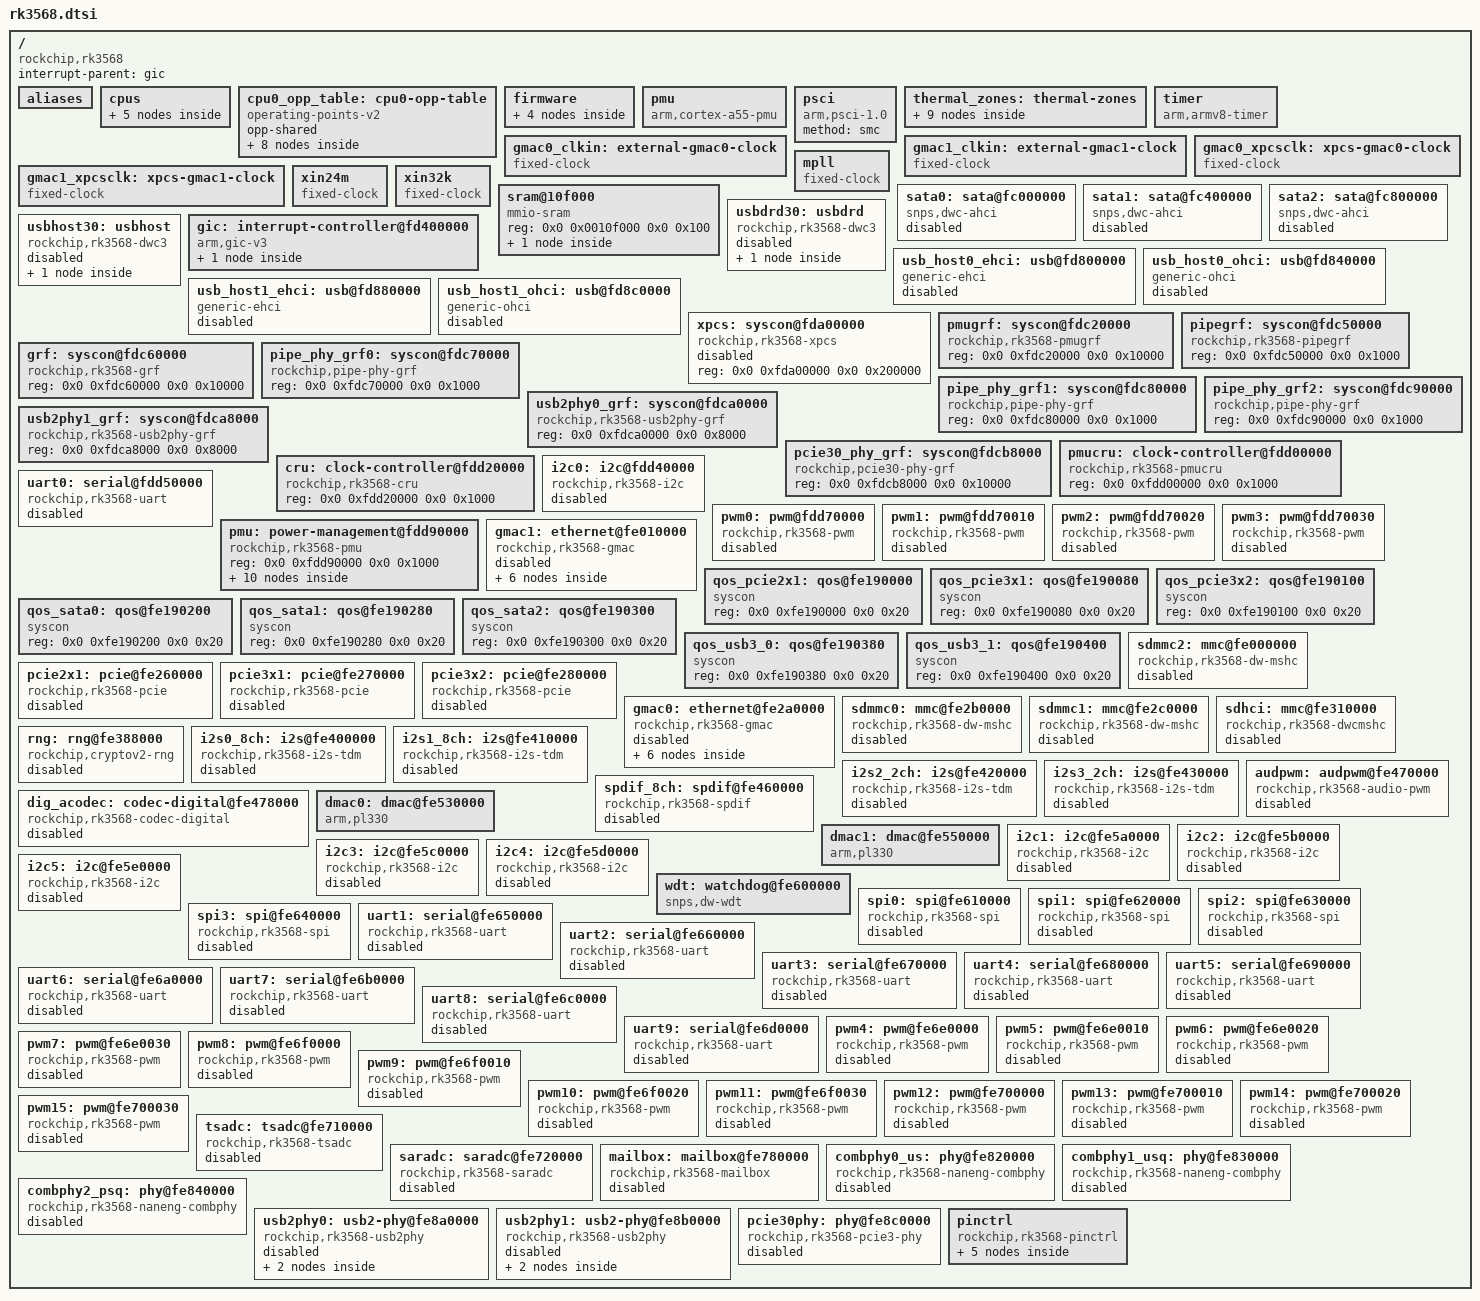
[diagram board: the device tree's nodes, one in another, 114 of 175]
// SPDX-License-Identifier: (GPL-2.0+ OR MIT)
/*
 * Copyright (c) 2021 Rockchip Electronics Co., Ltd.
 */

#include <dt-bindings/clock/rk3568-cru.h>
#include <dt-bindings/interrupt-controller/arm-gic.h>
#include <dt-bindings/interrupt-controller/irq.h>
#include <dt-bindings/phy/phy.h>
#include <dt-bindings/pinctrl/rockchip.h>
#include <dt-bindings/power/rk3568-power.h>
#include <dt-bindings/soc/rockchip,boot-mode.h>
#include <dt-bindings/thermal/thermal.h>

/ {
	compatible = "rockchip,rk3568";

	interrupt-parent = <&gic>;
	#address-cells = <2>;
	#size-cells = <2>;

	aliases {
		ethernet0 = &gmac0;
		ethernet1 = &gmac1;
		gpio0 = &gpio0;
		gpio1 = &gpio1;
		gpio2 = &gpio2;
		gpio3 = &gpio3;
		gpio4 = &gpio4;
		i2c0 = &i2c0;
		i2c1 = &i2c1;
		i2c2 = &i2c2;
		i2c3 = &i2c3;
		i2c4 = &i2c4;
		i2c5 = &i2c5;
		serial0 = &uart0;
		serial1 = &uart1;
		serial2 = &uart2;
		serial3 = &uart3;
		serial4 = &uart4;
		serial5 = &uart5;
		serial6 = &uart6;
		serial7 = &uart7;
		serial8 = &uart8;
		serial9 = &uart9;
		spi0 = &spi0;
		spi1 = &spi1;
		spi2 = &spi2;
		spi3 = &spi3;
	};

	cpus {
		#address-cells = <2>;
		#size-cells = <0>;

		cpu0: cpu@0 {
			device_type = "cpu";
			compatible = "arm,cortex-a55";
			reg = <0x0 0x0>;
			clocks = <&scmi_clk 0>;
			enable-method = "psci";
			operating-points-v2 = <&cpu0_opp_table>;
			#cooling-cells = <2>;
			dynamic-power-coefficient = <187>;
			power-model {
				compatible = "simple-power-model";
				leakage-range= <10 40>;
				ls = <(-9196) 6360 0>;
				static-coefficient = <100000>;
				ts = <83822 206397 (-4300) 71>;
				thermal-zone = "soc-thermal";
			};
		};

		cpu1: cpu@100 {
			device_type = "cpu";
			compatible = "arm,cortex-a55";
			reg = <0x0 0x100>;
			clocks = <&scmi_clk 0>;
			enable-method = "psci";
			operating-points-v2 = <&cpu0_opp_table>;
		};

		cpu2: cpu@200 {
			device_type = "cpu";
			compatible = "arm,cortex-a55";
			reg = <0x0 0x200>;
			clocks = <&scmi_clk 0>;
			enable-method = "psci";
			operating-points-v2 = <&cpu0_opp_table>;
		};

		cpu3: cpu@300 {
			device_type = "cpu";
			compatible = "arm,cortex-a55";
			reg = <0x0 0x300>;
			clocks = <&scmi_clk 0>;
			enable-method = "psci";
			operating-points-v2 = <&cpu0_opp_table>;
		};
	};

	cpu0_opp_table: cpu0-opp-table {
		compatible = "operating-points-v2";
		opp-shared;

		opp-408000000 {
			opp-hz = /bits/ 64 <408000000>;
			opp-microvolt = <900000 900000 1150000>;
			clock-latency-ns = <40000>;
		};

		opp-600000000 {
			opp-hz = /bits/ 64 <600000000>;
			opp-microvolt = <900000 900000 1150000>;
			clock-latency-ns = <40000>;
		};

		opp-816000000 {
			opp-hz = /bits/ 64 <816000000>;
			opp-microvolt = <900000 900000 1150000>;
			clock-latency-ns = <40000>;
			opp-suspend;
		};

		opp-1104000000 {
			opp-hz = /bits/ 64 <1104000000>;
			opp-microvolt = <900000 900000 1150000>;
			clock-latency-ns = <40000>;
		};

		opp-1416000000 {
			opp-hz = /bits/ 64 <1416000000>;
			opp-microvolt = <900000 900000 1150000>;
			clock-latency-ns = <40000>;
		};

		opp-1608000000 {
			opp-hz = /bits/ 64 <1608000000>;
			opp-microvolt = <975000 975000 1150000>;
			clock-latency-ns = <40000>;
		};

		opp-1800000000 {
			opp-hz = /bits/ 64 <1800000000>;
			opp-microvolt = <1050000 1050000 1150000>;
			clock-latency-ns = <40000>;
		};

		opp-1992000000 {
			opp-hz = /bits/ 64 <1992000000>;
			opp-microvolt = <1150000 1150000 1150000>;
			clock-latency-ns = <40000>;
		};
	};

	firmware {
		optee: optee {
			compatible = "linaro,optee-tz";
			method = "smc";
		};

		scmi: scmi {
			compatible = "arm,scmi-smc";
			arm,smc-id = <0x82000010>;
			shmem = <&scmi_shmem>;
			#address-cells = <1>;
			#size-cells = <0>;

			scmi_clk: protocol@14 {
				reg = <0x14>;
				#clock-cells = <1>;
			};
		};

		sdei: sdei {
			compatible = "arm,sdei-1.0";
			method = "smc";
		};
	};

	pmu {
		compatible = "arm,cortex-a55-pmu";
		interrupts = <GIC_SPI 228 IRQ_TYPE_LEVEL_HIGH>,
			     <GIC_SPI 229 IRQ_TYPE_LEVEL_HIGH>,
			     <GIC_SPI 230 IRQ_TYPE_LEVEL_HIGH>,
			     <GIC_SPI 231 IRQ_TYPE_LEVEL_HIGH>;
		interrupt-affinity = <&cpu0>, <&cpu1>, <&cpu2>, <&cpu3>;
	};

	psci {
		compatible = "arm,psci-1.0";
		method = "smc";
	};

	thermal_zones: thermal-zones {
		soc_thermal: soc-thermal {
			polling-delay-passive = <20>; /* milliseconds */
			polling-delay = <1000>; /* milliseconds */
			sustainable-power = <1475>; /* milliwatts */

			thermal-sensors = <&tsadc 0>;
			trips {
				threshold: trip-point-0 {
					temperature = <70000>;
					hysteresis = <2000>;
					type = "passive";
				};
				target: trip-point-1 {
					temperature = <85000>;
					hysteresis = <2000>;
					type = "passive";
				};
				soc_crit: soc-crit {
					/* millicelsius */
					temperature = <115000>;
					/* millicelsius */
					hysteresis = <2000>;
					type = "critical";
				};
			};
			cooling-maps {
				map0 {
					trip = <&target>;
					cooling-device = <&cpu0 THERMAL_NO_LIMIT THERMAL_NO_LIMIT>;
					contribution = <1024>;
				};
				map1 {
					trip = <&target>;
					cooling-device = <&gpu THERMAL_NO_LIMIT THERMAL_NO_LIMIT>;
					contribution = <1024>;
				};
			};
		};

		gpu_thermal: gpu-thermal {
			polling-delay-passive = <20>; /* milliseconds */
			polling-delay = <1000>; /* milliseconds */

			thermal-sensors = <&tsadc 1>;
		};
	};

	timer {
		compatible = "arm,armv8-timer";
		interrupts = <GIC_PPI 13 IRQ_TYPE_LEVEL_HIGH>,
			     <GIC_PPI 14 IRQ_TYPE_LEVEL_HIGH>,
			     <GIC_PPI 11 IRQ_TYPE_LEVEL_HIGH>,
			     <GIC_PPI 10 IRQ_TYPE_LEVEL_HIGH>;
		arm,no-tick-in-suspend;
	};

	gmac0_clkin: external-gmac0-clock {
		compatible = "fixed-clock";
		clock-frequency = <125000000>;
		clock-output-names = "gmac0_clkin";
		#clock-cells = <0>;
	};

	gmac1_clkin: external-gmac1-clock {
		compatible = "fixed-clock";
		clock-frequency = <125000000>;
		clock-output-names = "gmac1_clkin";
		#clock-cells = <0>;
	};

	gmac0_xpcsclk: xpcs-gmac0-clock {
		compatible = "fixed-clock";
		clock-frequency = <125000000>;
		clock-output-names = "clk_gmac0_xpcs_mii";
		#clock-cells = <0>;
	};

	gmac1_xpcsclk: xpcs-gmac1-clock {
		compatible = "fixed-clock";
		clock-frequency = <125000000>;
		clock-output-names = "clk_gmac1_xpcs_mii";
		#clock-cells = <0>;
	};

	mpll: mpll {
		compatible = "fixed-clock";
		clock-frequency = <800000000>;
		clock-output-names = "mpll";
		#clock-cells = <0>;
	};

	xin24m: xin24m {
		compatible = "fixed-clock";
		clock-frequency = <24000000>;
		clock-output-names = "xin24m";
		#clock-cells = <0>;
	};

	xin32k: xin32k {
		compatible = "fixed-clock";
		clock-frequency = <32768>;
		clock-output-names = "xin32k";
		pinctrl-0 = <&clk32k_out0>;
		pinctrl-names = "default";
		#clock-cells = <0>;
	};

	sram@10f000 {
		compatible = "mmio-sram";
		reg = <0x0 0x0010f000 0x0 0x100>;
		#address-cells = <1>;
		#size-cells = <1>;
		ranges = <0 0x0 0x0010f000 0x100>;

		scmi_shmem: sram@0 {
			compatible = "arm,scmi-shmem";
			reg = <0x0 0x100>;
		};
	};

	sata0: sata@fc000000 {
		compatible = "snps,dwc-ahci";
		reg = <0 0xfc000000 0 0x1000>;
		clocks = <&cru ACLK_SATA0>, <&cru CLK_SATA0_PMALIVE>,
			 <&cru CLK_SATA0_RXOOB>;
		clock-names = "sata", "pmalive", "rxoob";
		interrupts = <GIC_SPI 94 IRQ_TYPE_LEVEL_HIGH>;
		interrupt-names = "hostc";
		phys = <&combphy0_us PHY_TYPE_SATA>;
		phy-names = "sata-phy";
		ports-implemented = <0x1>;
		power-domains = <&power RK3568_PD_PIPE>;
		status = "disabled";
	};

	sata1: sata@fc400000 {
		compatible = "snps,dwc-ahci";
		reg = <0 0xfc400000 0 0x1000>;
		clocks = <&cru ACLK_SATA1>, <&cru CLK_SATA1_PMALIVE>,
			 <&cru CLK_SATA1_RXOOB>;
		clock-names = "sata", "pmalive", "rxoob";
		interrupts = <GIC_SPI 95 IRQ_TYPE_LEVEL_HIGH>;
		interrupt-names = "hostc";
		phys = <&combphy1_usq PHY_TYPE_SATA>;
		phy-names = "sata-phy";
		ports-implemented = <0x1>;
		power-domains = <&power RK3568_PD_PIPE>;
		status = "disabled";
	};

	sata2: sata@fc800000 {
		compatible = "snps,dwc-ahci";
		reg = <0 0xfc800000 0 0x1000>;
		clocks = <&cru ACLK_SATA2>, <&cru CLK_SATA2_PMALIVE>,
			 <&cru CLK_SATA2_RXOOB>;
		clock-names = "sata", "pmalive", "rxoob";
		interrupts = <GIC_SPI 96 IRQ_TYPE_LEVEL_HIGH>;
		interrupt-names = "hostc";
		phys = <&combphy2_psq PHY_TYPE_SATA>;
		phy-names = "sata-phy";
		ports-implemented = <0x1>;
		power-domains = <&power RK3568_PD_PIPE>;
		status = "disabled";
	};

	usbdrd30: usbdrd {
		compatible = "rockchip,rk3568-dwc3", "rockchip,rk3399-dwc3";
		clocks = <&cru CLK_USB3OTG0_REF>, <&cru CLK_USB3OTG0_SUSPEND>,
			 <&cru ACLK_USB3OTG0>, <&cru PCLK_PIPE>;
		clock-names = "ref_clk", "suspend_clk",
			      "bus_clk", "pipe_clk";
		#address-cells = <2>;
		#size-cells = <2>;
		ranges;
		status = "disabled";

		usbdrd_dwc3: dwc3@fcc00000 {
			compatible = "snps,dwc3";
			reg = <0x0 0xfcc00000 0x0 0x400000>;
			interrupts = <GIC_SPI 169 IRQ_TYPE_LEVEL_HIGH>;
			dr_mode = "otg";
			phys = <&u2phy0_otg>, <&combphy0_us PHY_TYPE_USB3>;
			phy-names = "usb2-phy", "usb3-phy";
			phy_type = "utmi_wide";
			power-domains = <&power RK3568_PD_PIPE>;
			resets = <&cru SRST_USB3OTG0>;
			reset-names = "usb3-otg";
			snps,dis_enblslpm_quirk;
			snps,dis-u2-freeclk-exists-quirk;
			snps,dis-del-phy-power-chg-quirk;
			snps,dis-tx-ipgap-linecheck-quirk;
			snps,xhci-trb-ent-quirk;
			status = "disabled";
		};
	};

	usbhost30: usbhost {
		compatible = "rockchip,rk3568-dwc3", "rockchip,rk3399-dwc3";
		clocks = <&cru CLK_USB3OTG1_REF>, <&cru CLK_USB3OTG1_SUSPEND>,
			 <&cru ACLK_USB3OTG1>, <&cru PCLK_PIPE>;
		clock-names = "ref_clk", "suspend_clk",
			      "bus_clk", "pipe_clk";
		#address-cells = <2>;
		#size-cells = <2>;
		ranges;
		status = "disabled";

		usbhost_dwc3: dwc3@fd000000 {
			compatible = "snps,dwc3";
			reg = <0x0 0xfd000000 0x0 0x400000>;
			interrupts = <GIC_SPI 170 IRQ_TYPE_LEVEL_HIGH>;
			dr_mode = "host";
			phys = <&u2phy0_host>, <&combphy1_usq PHY_TYPE_USB3>;
			phy-names = "usb2-phy", "usb3-phy";
			phy_type = "utmi_wide";
			power-domains = <&power RK3568_PD_PIPE>;
			resets = <&cru SRST_USB3OTG1>;
			reset-names = "usb3-host";
			snps,dis_enblslpm_quirk;
			snps,dis-u2-freeclk-exists-quirk;
			snps,dis-del-phy-power-chg-quirk;
			snps,dis-tx-ipgap-linecheck-quirk;
			snps,xhci-trb-ent-quirk;
			status = "disabled";
		};
	};

	gic: interrupt-controller@fd400000 {
		compatible = "arm,gic-v3";
		#interrupt-cells = <3>;
		#address-cells = <2>;
		#size-cells = <2>;
		ranges;
		interrupt-controller;

		reg = <0x0 0xfd400000 0 0x10000>, /* GICD */
		      <0x0 0xfd460000 0 0xc0000>; /* GICR */
		interrupts = <GIC_PPI 9 IRQ_TYPE_LEVEL_HIGH>;
		its: interrupt-controller@fd440000 {
			compatible = "arm,gic-v3-its";
			msi-controller;
			#msi-cells = <1>;
			reg = <0x0 0xfd440000 0x0 0x20000>;
		};
	};

	usb_host0_ehci: usb@fd800000 {
		compatible = "generic-ehci";
		reg = <0x0 0xfd800000 0x0 0x40000>;
		interrupts = <GIC_SPI 130 IRQ_TYPE_LEVEL_HIGH>;
		clocks = <&cru HCLK_USB2HOST0>, <&cru HCLK_USB2HOST0_ARB>,
			 <&cru PCLK_USB>, <&usb2phy1>;
		clock-names = "usbhost", "arbiter", "pclk", "utmi";
		phys = <&u2phy1_otg>;
		phy-names = "usb2-phy";
		status = "disabled";
	};

	usb_host0_ohci: usb@fd840000 {
		compatible = "generic-ohci";
		reg = <0x0 0xfd840000 0x0 0x40000>;
		interrupts = <GIC_SPI 131 IRQ_TYPE_LEVEL_HIGH>;
		clocks = <&cru HCLK_USB2HOST0>, <&cru HCLK_USB2HOST0_ARB>,
			 <&cru PCLK_USB>, <&usb2phy1>;
		clock-names = "usbhost", "arbiter", "pclk", "utmi";
		phys = <&u2phy1_otg>;
		phy-names = "usb2-phy";
		status = "disabled";
	};

	usb_host1_ehci: usb@fd880000 {
		compatible = "generic-ehci";
		reg = <0x0 0xfd880000 0x0 0x40000>;
		interrupts = <GIC_SPI 133 IRQ_TYPE_LEVEL_HIGH>;
		clocks = <&cru HCLK_USB2HOST1>, <&cru HCLK_USB2HOST1_ARB>,
			 <&cru PCLK_USB>, <&usb2phy1>;
		clock-names = "usbhost", "arbiter", "pclk", "utmi";
		phys = <&u2phy1_host>;
		phy-names = "usb2-phy";
		status = "disabled";
	};

	usb_host1_ohci: usb@fd8c0000 {
		compatible = "generic-ohci";
		reg = <0x0 0xfd8c0000 0x0 0x40000>;
		interrupts = <GIC_SPI 134 IRQ_TYPE_LEVEL_HIGH>;
		clocks = <&cru HCLK_USB2HOST1>, <&cru HCLK_USB2HOST1_ARB>,
			 <&cru PCLK_USB>, <&usb2phy1>;
		clock-names = "usbhost", "arbiter", "pclk", "utmi";
		phys = <&u2phy1_host>;
		phy-names = "usb2-phy";
		status = "disabled";
	};

	xpcs: syscon@fda00000 {
		compatible = "rockchip,rk3568-xpcs", "syscon";
		reg = <0x0 0xfda00000 0x0 0x200000>;
		status = "disabled";
	};

	pmugrf: syscon@fdc20000 {
		compatible = "rockchip,rk3568-pmugrf", "syscon", "simple-mfd";
		reg = <0x0 0xfdc20000 0x0 0x10000>;
	};

	pipegrf: syscon@fdc50000 {
		compatible = "rockchip,rk3568-pipegrf", "syscon";
		reg = <0x0 0xfdc50000 0x0 0x1000>;
	};

	grf: syscon@fdc60000 {
		compatible = "rockchip,rk3568-grf", "syscon", "simple-mfd";
		reg = <0x0 0xfdc60000 0x0 0x10000>;
	};

	pipe_phy_grf0: syscon@fdc70000 {
		compatible = "rockchip,pipe-phy-grf", "syscon";
		reg = <0x0 0xfdc70000 0x0 0x1000>;
	};

	pipe_phy_grf1: syscon@fdc80000 {
		compatible = "rockchip,pipe-phy-grf", "syscon";
		reg = <0x0 0xfdc80000 0x0 0x1000>;
	};

	pipe_phy_grf2: syscon@fdc90000 {
		compatible = "rockchip,pipe-phy-grf", "syscon";
		reg = <0x0 0xfdc90000 0x0 0x1000>;
	};

	usb2phy0_grf: syscon@fdca0000 {
		compatible = "rockchip,rk3568-usb2phy-grf", "syscon";
		reg = <0x0 0xfdca0000 0x0 0x8000>;
	};

	usb2phy1_grf: syscon@fdca8000 {
		compatible = "rockchip,rk3568-usb2phy-grf", "syscon";
		reg = <0x0 0xfdca8000 0x0 0x8000>;
	};

	pcie30_phy_grf: syscon@fdcb8000 {
		compatible = "rockchip,pcie30-phy-grf", "syscon";
		reg = <0x0 0xfdcb8000 0x0 0x10000>;
	};

	pmucru: clock-controller@fdd00000 {
		compatible = "rockchip,rk3568-pmucru";
		reg = <0x0 0xfdd00000 0x0 0x1000>;
		#clock-cells = <1>;
		#reset-cells = <1>;
	};

	cru: clock-controller@fdd20000 {
		compatible = "rockchip,rk3568-cru";
		reg = <0x0 0xfdd20000 0x0 0x1000>;
		#clock-cells = <1>;
		#reset-cells = <1>;
	};

	i2c0: i2c@fdd40000 {
		compatible = "rockchip,rk3568-i2c", "rockchip,rk3399-i2c";
		reg = <0x0 0xfdd40000 0x0 0x1000>;
		interrupts = <GIC_SPI 46 IRQ_TYPE_LEVEL_HIGH>;
		clocks = <&pmucru CLK_I2C0>, <&pmucru PCLK_I2C0>;
		clock-names = "i2c", "pclk";
		pinctrl-0 = <&i2c0_xfer>;
		pinctrl-names = "default";
		#address-cells = <1>;
		#size-cells = <0>;
		status = "disabled";
	};

	uart0: serial@fdd50000 {
		compatible = "rockchip,rk3568-uart", "snps,dw-apb-uart";
		reg = <0x0 0xfdd50000 0x0 0x100>;
		interrupts = <GIC_SPI 116 IRQ_TYPE_LEVEL_HIGH>;
		clocks = <&pmucru SCLK_UART0>, <&pmucru PCLK_UART0>;
		clock-names = "baudclk", "apb_pclk";
		dmas = <&dmac0 0>, <&dmac0 1>;
		pinctrl-0 = <&uart0_xfer>;
		pinctrl-names = "default";
		reg-io-width = <4>;
		reg-shift = <2>;
		status = "disabled";
	};

	pwm0: pwm@fdd70000 {
		compatible = "rockchip,rk3568-pwm", "rockchip,rk3328-pwm";
		reg = <0x0 0xfdd70000 0x0 0x10>;
		#pwm-cells = <3>;
		pinctrl-names = "active";
		pinctrl-0 = <&pwm0m0_pins>;
		clocks = <&pmucru CLK_PWM0>, <&pmucru PCLK_PWM0>;
		clock-names = "pwm", "pclk";
		status = "disabled";
	};

	pwm1: pwm@fdd70010 {
		compatible = "rockchip,rk3568-pwm", "rockchip,rk3328-pwm";
		reg = <0x0 0xfdd70010 0x0 0x10>;
		#pwm-cells = <3>;
		pinctrl-names = "active";
		pinctrl-0 = <&pwm1m0_pins>;
		clocks = <&pmucru CLK_PWM0>, <&pmucru PCLK_PWM0>;
		clock-names = "pwm", "pclk";
		status = "disabled";
	};

	pwm2: pwm@fdd70020 {
		compatible = "rockchip,rk3568-pwm", "rockchip,rk3328-pwm";
		reg = <0x0 0xfdd70020 0x0 0x10>;
		#pwm-cells = <3>;
		pinctrl-names = "active";
		pinctrl-0 = <&pwm2m0_pins>;
		clocks = <&pmucru CLK_PWM0>, <&pmucru PCLK_PWM0>;
		clock-names = "pwm", "pclk";
		status = "disabled";
	};

	pwm3: pwm@fdd70030 {
		compatible = "rockchip,rk3568-pwm", "rockchip,rk3328-pwm";
		reg = <0x0 0xfdd70030 0x0 0x10>;
		#pwm-cells = <3>;
		pinctrl-names = "active";
		pinctrl-0 = <&pwm3_pins>;
		clocks = <&pmucru CLK_PWM0>, <&pmucru PCLK_PWM0>;
		clock-names = "pwm", "pclk";
		status = "disabled";
	};

	pmu: power-management@fdd90000 {
		compatible = "rockchip,rk3568-pmu", "syscon", "simple-mfd";
		reg = <0x0 0xfdd90000 0x0 0x1000>;

		power: power-controller {
			compatible = "rockchip,rk3568-power-controller";
			#power-domain-cells = <1>;
			#address-cells = <1>;
			#size-cells = <0>;
			status = "okay";

			/* These power domains are grouped by VD_NPU */
			pd_npu@RK3568_PD_NPU {
				reg = <RK3568_PD_NPU>;
				clocks = <&cru ACLK_NPU_PRE>,
					 <&cru HCLK_NPU_PRE>,
					 <&cru PCLK_NPU_PRE>;
				pm_qos = <&qos_npu>;
			};
			/* These power domains are grouped by VD_GPU */
			pd_gpu@RK3568_PD_GPU {
				reg = <RK3568_PD_GPU>;
				clocks = <&cru ACLK_GPU_PRE>,
					 <&cru PCLK_GPU_PRE>;
				pm_qos = <&qos_gpu>;
			};
			/* These power domains are grouped by VD_LOGIC */
			pd_vi@RK3568_PD_VI {
				reg = <RK3568_PD_VI>;
				clocks = <&cru HCLK_VI>,
					 <&cru PCLK_VI>;
				pm_qos = <&qos_isp>,
					 <&qos_vicap0>,
					 <&qos_vicap1>;
			};
			pd_vo@RK3568_PD_VO {
				reg = <RK3568_PD_VO>;
				clocks = <&cru HCLK_VO>,
					 <&cru PCLK_VO>,
					 <&cru ACLK_VOP_PRE>;
				pm_qos = <&qos_hdcp>,
					 <&qos_vop_m0>,
					 <&qos_vop_m1>;
			};
			pd_rga@RK3568_PD_RGA {
				reg = <RK3568_PD_RGA>;
				clocks = <&cru HCLK_RGA_PRE>,
					 <&cru PCLK_RGA_PRE>;
				pm_qos = <&qos_ebc>,
					 <&qos_iep>,
					 <&qos_jpeg_dec>,
					 <&qos_jpeg_enc>,
					 <&qos_rga_rd>,
					 <&qos_rga_wr>;
			};
			pd_vpu@RK3568_PD_VPU {
				reg = <RK3568_PD_VPU>;
				clocks = <&cru HCLK_VPU_PRE>;
				pm_qos = <&qos_vpu>;
			};
			pd_rkvdec@RK3568_PD_RKVDEC {
				clocks = <&cru HCLK_RKVDEC_PRE>;
				reg = <RK3568_PD_RKVDEC>;
				pm_qos = <&qos_rkvdec>;
			};
			pd_rkvenc@RK3568_PD_RKVENC {
				reg = <RK3568_PD_RKVENC>;
				clocks = <&cru HCLK_RKVENC_PRE>;
				pm_qos = <&qos_rkvenc_rd_m0>,
					 <&qos_rkvenc_rd_m1>,
					 <&qos_rkvenc_wr_m0>;
			};
			pd_pipe@RK3568_PD_PIPE {
				reg = <RK3568_PD_PIPE>;
				clocks = <&cru PCLK_PIPE>;
				pm_qos = <&qos_pcie2x1>,
					 <&qos_pcie3x1>,
					 <&qos_pcie3x2>,
					 <&qos_sata0>,
					 <&qos_sata1>,
					 <&qos_sata2>,
					 <&qos_usb3_0>,
					 <&qos_usb3_1>;
			};
		};
	};

	gmac1: ethernet@fe010000 {
		compatible = "rockchip,rk3568-gmac", "snps,dwmac-4.20a";
		reg = <0x0 0xfe010000 0x0 0x10000>;
		interrupts = <GIC_SPI 32 IRQ_TYPE_LEVEL_HIGH>,
			     <GIC_SPI 29 IRQ_TYPE_LEVEL_HIGH>;
		interrupt-names = "macirq", "eth_wake_irq";
		rockchip,grf = <&grf>;
		clocks = <&cru SCLK_GMAC1>, <&cru SCLK_GMAC1_RX_TX>,
			 <&cru SCLK_GMAC1_RX_TX>, <&cru CLK_MAC1_REFOUT>,
			 <&cru ACLK_GMAC1>, <&cru PCLK_GMAC1>,
			 <&cru SCLK_GMAC1_RX_TX>, <&cru CLK_GMAC1_PTP_REF>,
			 <&cru PCLK_XPCS>;
		clock-names = "stmmaceth", "mac_clk_rx",
			      "mac_clk_tx", "clk_mac_refout",
			      "aclk_mac", "pclk_mac",
			      "clk_mac_speed", "ptp_ref",
			      "pclk_xpcs";
		resets = <&cru SRST_A_GMAC1>;
		reset-names = "stmmaceth";

		snps,mixed-burst;
		snps,tso;

		snps,axi-config = <&gmac1_stmmac_axi_setup>;
		snps,mtl-rx-config = <&gmac1_mtl_rx_setup>;
		snps,mtl-tx-config = <&gmac1_mtl_tx_setup>;
		status = "disabled";

		mdio1: mdio {
			compatible = "snps,dwmac-mdio";
			#address-cells = <0x1>;
			#size-cells = <0x0>;
		};

		gmac1_stmmac_axi_setup: stmmac-axi-config {
			snps,wr_osr_lmt = <4>;
			snps,rd_osr_lmt = <8>;
			snps,blen = <0 0 0 0 16 8 4>;
		};

		gmac1_mtl_rx_setup: rx-queues-config {
			snps,rx-queues-to-use = <1>;
			queue0 {};
		};

		gmac1_mtl_tx_setup: tx-queues-config {
			snps,tx-queues-to-use = <1>;
			queue0 {};
		};
	};

	qos_pcie2x1: qos@fe190000 {
		compatible = "syscon";
		reg = <0x0 0xfe190000 0x0 0x20>;
	};

	qos_pcie3x1: qos@fe190080 {
		compatible = "syscon";
		reg = <0x0 0xfe190080 0x0 0x20>;
	};

	qos_pcie3x2: qos@fe190100 {
		compatible = "syscon";
		reg = <0x0 0xfe190100 0x0 0x20>;
	};

	qos_sata0: qos@fe190200 {
		compatible = "syscon";
		reg = <0x0 0xfe190200 0x0 0x20>;
	};

	qos_sata1: qos@fe190280 {
		compatible = "syscon";
		reg = <0x0 0xfe190280 0x0 0x20>;
	};

	qos_sata2: qos@fe190300 {
		compatible = "syscon";
		reg = <0x0 0xfe190300 0x0 0x20>;
	};

	qos_usb3_0: qos@fe190380 {
		compatible = "syscon";
		reg = <0x0 0xfe190380 0x0 0x20>;
	};

	qos_usb3_1: qos@fe190400 {
		compatible = "syscon";
		reg = <0x0 0xfe190400 0x0 0x20>;
	};

	sdmmc2: mmc@fe000000 {
		compatible = "rockchip,rk3568-dw-mshc", "rockchip,rk3288-dw-mshc";
		reg = <0x0 0xfe000000 0x0 0x4000>;
		interrupts = <GIC_SPI 100 IRQ_TYPE_LEVEL_HIGH>;
		clocks = <&cru HCLK_SDMMC2>, <&cru CLK_SDMMC2>,
			 <&cru SCLK_SDMMC2_DRV>, <&cru SCLK_SDMMC2_SAMPLE>;
		clock-names = "biu", "ciu", "ciu-drive", "ciu-sample";
		fifo-depth = <0x100>;
		max-frequency = <150000000>;
		resets = <&cru SRST_SDMMC2>;
		reset-names = "reset";
		status = "disabled";
	};

	pcie2x1: pcie@fe260000 {
		compatible = "rockchip,rk3568-pcie", "snps,dw-pcie";
		#address-cells = <3>;
		#size-cells = <2>;
		bus-range = <0x0 0xf>;
		clocks = <&cru ACLK_PCIE20_MST>, <&cru ACLK_PCIE20_SLV>,
			 <&cru ACLK_PCIE20_DBI>, <&cru PCLK_PCIE20>,
			 <&cru CLK_PCIE20_AUX_NDFT>;
		clock-names = "aclk_mst", "aclk_slv",
			      "aclk_dbi", "pclk", "aux";
		device_type = "pci";
		interrupts = <GIC_SPI 75 IRQ_TYPE_LEVEL_HIGH>,
			     <GIC_SPI 74 IRQ_TYPE_LEVEL_HIGH>,
			     <GIC_SPI 73 IRQ_TYPE_LEVEL_HIGH>,
			     <GIC_SPI 72 IRQ_TYPE_LEVEL_HIGH>,
			     <GIC_SPI 71 IRQ_TYPE_LEVEL_HIGH>;
		interrupt-names = "sys", "pmc", "msg", "legacy", "err";
		linux,pci-domain = <0>;
		num-ib-windows = <6>;
		num-ob-windows = <2>;
		max-link-speed = <2>;
		msi-map = <0x0 &its 0x0 0x1000>;
		num-lanes = <1>;
		phys = <&combphy2_psq PHY_TYPE_PCIE>;
		phy-names = "pcie-phy";
		power-domains = <&power RK3568_PD_PIPE>;
		ranges = <0x00000800 0x0 0x00000000 0x3 0x00000000 0x0 0x800000
			  0x81000000 0x0 0x00800000 0x3 0x00800000 0x0 0x100000
			  0x83000000 0x0 0x00900000 0x3 0x00900000 0x0 0x3f700000>;
		reg = <0x3 0xc0000000 0x0 0x400000>,
		      <0x0 0xfe260000 0x0 0x10000>;
		reg-names = "pcie-dbi", "pcie-apb";
		resets = <&cru SRST_PCIE20_POWERUP>;
		reset-names = "pipe";
		status = "disabled";
	};

	pcie3x1: pcie@fe270000 {
		compatible = "rockchip,rk3568-pcie", "snps,dw-pcie";
		#address-cells = <3>;
		#size-cells = <2>;
		bus-range = <0x10 0x1f>;
		clocks = <&cru ACLK_PCIE30X1_MST>, <&cru ACLK_PCIE30X1_SLV>,
			 <&cru ACLK_PCIE30X1_DBI>, <&cru PCLK_PCIE30X1>,
			 <&cru CLK_PCIE30X1_AUX_NDFT>;
		clock-names = "aclk_mst", "aclk_slv",
			      "aclk_dbi", "pclk", "aux";
		device_type = "pci";
		interrupts = <GIC_SPI 160 IRQ_TYPE_LEVEL_HIGH>,
			     <GIC_SPI 159 IRQ_TYPE_LEVEL_HIGH>,
			     <GIC_SPI 158 IRQ_TYPE_LEVEL_HIGH>,
			     <GIC_SPI 157 IRQ_TYPE_LEVEL_HIGH>,
			     <GIC_SPI 156 IRQ_TYPE_LEVEL_HIGH>;
		interrupt-names = "sys", "pmc", "msg", "legacy", "err";
		linux,pci-domain = <1>;
		num-ib-windows = <6>;
		num-ob-windows = <2>;
		max-link-speed = <3>;
		msi-map = <0x1000 &its 0x1000 0x1000>;
		num-lanes = <1>;
		phys = <&pcie30phy>;
		phy-names = "pcie-phy";
		power-domains = <&power RK3568_PD_PIPE>;
		ranges = <0x00000800 0x0 0x40000000 0x3 0x40000000 0x0 0x800000
			  0x81000000 0x0 0x40800000 0x3 0x40800000 0x0 0x100000
			  0x83000000 0x0 0x40900000 0x3 0x40900000 0x0 0x3f700000>;
		reg = <0x3 0xc0400000 0x0 0x400000>,
		      <0x0 0xfe270000 0x0 0x10000>;
		reg-names = "pcie-dbi", "pcie-apb";
		resets = <&cru SRST_PCIE30X1_POWERUP>;
		reset-names = "pipe";
		/* rockchip,bifurcation; lane1 when using 1+1 */
		status = "disabled";
	};

	pcie3x2: pcie@fe280000 {
		compatible = "rockchip,rk3568-pcie", "snps,dw-pcie";
		#address-cells = <3>;
		#size-cells = <2>;
		bus-range = <0x20 0x2f>;
		clocks = <&cru ACLK_PCIE30X2_MST>, <&cru ACLK_PCIE30X2_SLV>,
			 <&cru ACLK_PCIE30X2_DBI>, <&cru PCLK_PCIE30X2>,
			 <&cru CLK_PCIE30X2_AUX_NDFT>;
		clock-names = "aclk_mst", "aclk_slv",
			      "aclk_dbi", "pclk", "aux";
		device_type = "pci";
		interrupts = <GIC_SPI 165 IRQ_TYPE_LEVEL_HIGH>,
			     <GIC_SPI 164 IRQ_TYPE_LEVEL_HIGH>,
			     <GIC_SPI 163 IRQ_TYPE_LEVEL_HIGH>,
			     <GIC_SPI 162 IRQ_TYPE_LEVEL_HIGH>,
			     <GIC_SPI 161 IRQ_TYPE_LEVEL_HIGH>;
		interrupt-names = "sys", "pmc", "msg", "legacy", "err";
		linux,pci-domain = <2>;
		num-ib-windows = <6>;
		num-ob-windows = <2>;
		max-link-speed = <3>;
		msi-map = <0x2000 &its 0x2000 0x1000>;
		num-lanes = <2>;
		phys = <&pcie30phy>;
		phy-names = "pcie-phy";
		power-domains = <&power RK3568_PD_PIPE>;
		ranges = <0x00000800 0x0 0x80000000 0x3 0x80000000 0x0 0x800000
			  0x81000000 0x0 0x80800000 0x3 0x80800000 0x0 0x100000
			  0x83000000 0x0 0x80900000 0x3 0x80900000 0x0 0x3f700000>;
		reg = <0x3 0xc0800000 0x0 0x400000>,
		      <0x0 0xfe280000 0x0 0x10000>;
		reg-names = "pcie-dbi", "pcie-apb";
		resets = <&cru SRST_PCIE30X2_POWERUP>;
		reset-names = "pipe";
		/* rockchip,bifurcation; lane0 when using 1+1 */
		status = "disabled";
	};

	gmac0: ethernet@fe2a0000 {
		compatible = "rockchip,rk3568-gmac", "snps,dwmac-4.20a";
		reg = <0x0 0xfe2a0000 0x0 0x10000>;
		interrupts = <GIC_SPI 27 IRQ_TYPE_LEVEL_HIGH>,
			     <GIC_SPI 24 IRQ_TYPE_LEVEL_HIGH>;
		interrupt-names = "macirq", "eth_wake_irq";
		rockchip,grf = <&grf>;
		clocks = <&cru SCLK_GMAC0>, <&cru SCLK_GMAC0_RX_TX>,
			 <&cru SCLK_GMAC0_RX_TX>, <&cru CLK_MAC0_REFOUT>,
			 <&cru ACLK_GMAC0>, <&cru PCLK_GMAC0>,
			 <&cru SCLK_GMAC0_RX_TX>, <&cru CLK_GMAC0_PTP_REF>,
			 <&cru PCLK_XPCS>;
		clock-names = "stmmaceth", "mac_clk_rx",
			      "mac_clk_tx", "clk_mac_refout",
			      "aclk_mac", "pclk_mac",
			      "clk_mac_speed", "ptp_ref",
			      "pclk_xpcs";
		resets = <&cru SRST_A_GMAC0>;
		reset-names = "stmmaceth";

		snps,mixed-burst;
		snps,tso;

		snps,axi-config = <&gmac0_stmmac_axi_setup>;
		snps,mtl-rx-config = <&gmac0_mtl_rx_setup>;
		snps,mtl-tx-config = <&gmac0_mtl_tx_setup>;
		status = "disabled";

		mdio0: mdio {
			compatible = "snps,dwmac-mdio";
			#address-cells = <0x1>;
			#size-cells = <0x0>;
		};

		gmac0_stmmac_axi_setup: stmmac-axi-config {
			snps,wr_osr_lmt = <4>;
			snps,rd_osr_lmt = <8>;
			snps,blen = <0 0 0 0 16 8 4>;
		};

		gmac0_mtl_rx_setup: rx-queues-config {
			snps,rx-queues-to-use = <1>;
			queue0 {};
		};

		gmac0_mtl_tx_setup: tx-queues-config {
			snps,tx-queues-to-use = <1>;
			queue0 {};
		};
	};

	sdmmc0: mmc@fe2b0000 {
		compatible = "rockchip,rk3568-dw-mshc", "rockchip,rk3288-dw-mshc";
		reg = <0x0 0xfe2b0000 0x0 0x4000>;
		interrupts = <GIC_SPI 98 IRQ_TYPE_LEVEL_HIGH>;
		clocks = <&cru HCLK_SDMMC0>, <&cru CLK_SDMMC0>,
			 <&cru SCLK_SDMMC0_DRV>, <&cru SCLK_SDMMC0_SAMPLE>;
		clock-names = "biu", "ciu", "ciu-drive", "ciu-sample";
		fifo-depth = <0x100>;
		max-frequency = <150000000>;
		resets = <&cru SRST_SDMMC0>;
		reset-names = "reset";
		status = "disabled";
	};

	sdmmc1: mmc@fe2c0000 {
		compatible = "rockchip,rk3568-dw-mshc", "rockchip,rk3288-dw-mshc";
		reg = <0x0 0xfe2c0000 0x0 0x4000>;
		interrupts = <GIC_SPI 99 IRQ_TYPE_LEVEL_HIGH>;
		clocks = <&cru HCLK_SDMMC1>, <&cru CLK_SDMMC1>,
			 <&cru SCLK_SDMMC1_DRV>, <&cru SCLK_SDMMC1_SAMPLE>;
		clock-names = "biu", "ciu", "ciu-drive", "ciu-sample";
		fifo-depth = <0x100>;
		max-frequency = <150000000>;
		resets = <&cru SRST_SDMMC1>;
		reset-names = "reset";
		status = "disabled";
	};

	sdhci: mmc@fe310000 {
		compatible = "rockchip,rk3568-dwcmshc";
		reg = <0x0 0xfe310000 0x0 0x10000>;
		interrupts = <GIC_SPI 19 IRQ_TYPE_LEVEL_HIGH>;
		assigned-clocks = <&cru BCLK_EMMC>, <&cru TCLK_EMMC>;
		assigned-clock-rates = <200000000>, <24000000>;
		clocks = <&cru CCLK_EMMC>, <&cru HCLK_EMMC>,
			 <&cru ACLK_EMMC>, <&cru BCLK_EMMC>,
			 <&cru TCLK_EMMC>;
		clock-names = "core", "bus", "axi", "block", "timer";
		status = "disabled";
	};

	rng: rng@fe388000 {
		compatible = "rockchip,cryptov2-rng";
		reg = <0x0 0xfe388000 0x0 0x2000>;
		clocks = <&cru CLK_TRNG_NS>, <&cru HCLK_TRNG_NS>;
		clock-names = "clk_trng", "hclk_trng";
		resets = <&cru SRST_TRNG_NS>;
		reset-names = "reset";
		status = "disabled";
	};

	i2s0_8ch: i2s@fe400000 {
		compatible = "rockchip,rk3568-i2s-tdm";
		reg = <0x0 0xfe400000 0x0 0x1000>;
		interrupts = <GIC_SPI 52 IRQ_TYPE_LEVEL_HIGH>;
		clocks = <&cru MCLK_I2S0_8CH_TX>, <&cru MCLK_I2S0_8CH_RX>, <&cru HCLK_I2S0_8CH>;
		clock-names = "mclk_tx", "mclk_rx", "hclk";
		dmas = <&dmac1 0>;
		dma-names = "tx";
		resets = <&cru SRST_M_I2S0_8CH_TX>, <&cru SRST_M_I2S0_8CH_RX>;
		reset-names = "tx-m", "rx-m";
		rockchip,cru = <&cru>;
		rockchip,grf = <&grf>;
		rockchip,playback-only;
		#sound-dai-cells = <0>;
		status = "disabled";
	};

	i2s1_8ch: i2s@fe410000 {
		compatible = "rockchip,rk3568-i2s-tdm";
		reg = <0x0 0xfe410000 0x0 0x1000>;
		interrupts = <GIC_SPI 53 IRQ_TYPE_LEVEL_HIGH>;
		clocks = <&cru MCLK_I2S1_8CH_TX>, <&cru MCLK_I2S1_8CH_RX>, <&cru HCLK_I2S1_8CH>;
		clock-names = "mclk_tx", "mclk_rx", "hclk";
		dmas = <&dmac1 2>, <&dmac1 3>;
		dma-names = "tx", "rx";
		resets = <&cru SRST_M_I2S1_8CH_TX>, <&cru SRST_M_I2S1_8CH_RX>;
		reset-names = "tx-m", "rx-m";
		rockchip,cru = <&cru>;
		rockchip,grf = <&grf>;
		#sound-dai-cells = <0>;
		pinctrl-names = "default";
		pinctrl-0 = <&i2s1m0_sclktx
			     &i2s1m0_sclkrx
			     &i2s1m0_lrcktx
			     &i2s1m0_lrckrx
			     &i2s1m0_sdi0
			     &i2s1m0_sdi1
			     &i2s1m0_sdi2
			     &i2s1m0_sdi3
			     &i2s1m0_sdo0
			     &i2s1m0_sdo1
			     &i2s1m0_sdo2
			     &i2s1m0_sdo3>;
		status = "disabled";
	};

	i2s2_2ch: i2s@fe420000 {
		compatible = "rockchip,rk3568-i2s-tdm";
		reg = <0x0 0xfe420000 0x0 0x1000>;
		interrupts = <GIC_SPI 54 IRQ_TYPE_LEVEL_HIGH>;
		clocks = <&cru MCLK_I2S2_2CH>, <&cru MCLK_I2S2_2CH>, <&cru HCLK_I2S2_2CH>;
		clock-names = "mclk_tx", "mclk_rx", "hclk";
		dmas = <&dmac1 4>, <&dmac1 5>;
		dma-names = "tx", "rx";
		rockchip,cru = <&cru>;
		rockchip,grf = <&grf>;
		rockchip,clk-trcm = <1>;
		#sound-dai-cells = <0>;
		pinctrl-names = "default";
		pinctrl-0 = <&i2s2m0_sclktx
			     &i2s2m0_lrcktx
			     &i2s2m0_sdi
			     &i2s2m0_sdo>;
		status = "disabled";
	};

	i2s3_2ch: i2s@fe430000 {
		compatible = "rockchip,rk3568-i2s-tdm";
		reg = <0x0 0xfe430000 0x0 0x1000>;
		interrupts = <GIC_SPI 55 IRQ_TYPE_LEVEL_HIGH>;
		clocks = <&cru MCLK_I2S3_2CH_TX>, <&cru MCLK_I2S3_2CH_RX>, <&cru HCLK_I2S3_2CH>;
		clock-names = "mclk_tx", "mclk_rx", "hclk";
		dmas = <&dmac1 6>, <&dmac1 7>;
		dma-names = "tx", "rx";
		resets = <&cru SRST_M_I2S3_2CH_TX>, <&cru SRST_M_I2S3_2CH_RX>;
		reset-names = "tx-m", "rx-m";
		rockchip,cru = <&cru>;
		rockchip,grf = <&grf>;
		#sound-dai-cells = <0>;
		pinctrl-names = "default";
		pinctrl-0 = <&i2s3m0_sclk
			     &i2s3m0_lrck
			     &i2s3m0_sdi
			     &i2s3m0_sdo>;
		status = "disabled";
	};

	spdif_8ch: spdif@fe460000 {
		compatible = "rockchip,rk3568-spdif";
		reg = <0x0 0xfe460000 0x0 0x1000>;
		interrupts = <GIC_SPI 102 IRQ_TYPE_LEVEL_HIGH>;
		dmas = <&dmac1 1>;
		dma-names = "tx";
		clock-names = "mclk", "hclk";
		clocks = <&cru MCLK_SPDIF_8CH>, <&cru HCLK_SPDIF_8CH>;
		#sound-dai-cells = <0>;
		pinctrl-names = "default";
		pinctrl-0 = <&spdifm0_tx>;
		status = "disabled";
	};

	audpwm: audpwm@fe470000 {
		compatible = "rockchip,rk3568-audio-pwm", "rockchip,audio-pwm-v1";
		reg = <0x0 0xfe470000 0x0 0x1000>;
		clocks = <&cru SCLK_AUDPWM>, <&cru HCLK_AUDPWM>;
		clock-names = "clk", "hclk";
		dmas = <&dmac1 8>;
		dma-names = "tx";
		#sound-dai-cells = <0>;
		rockchip,sample-width-bits = <11>;
		rockchip,interpolat-points = <1>;
		status = "disabled";
	};

	dig_acodec: codec-digital@fe478000 {
		compatible = "rockchip,rk3568-codec-digital", "rockchip,codec-digital-v1";
		reg = <0x0 0xfe478000 0x0 0x1000>;
		clocks = <&cru CLK_ACDCDIG_ADC>, <&cru CLK_ACDCDIG_DAC>,
			 <&cru CLK_ACDCDIG_I2C>, <&cru HCLK_ACDCDIG>;
		clock-names = "adc", "dac", "i2c", "pclk";
		pinctrl-names = "default";
		pinctrl-0 = <&acodec_pins>;
		resets = <&cru SRST_ACDCDIG>;
		reset-names = "reset" ;
		rockchip,grf = <&grf>;
		#sound-dai-cells = <0>;
		status = "disabled";
	};

	dmac0: dmac@fe530000 {
		compatible = "arm,pl330", "arm,primecell";
		reg = <0x0 0xfe530000 0x0 0x4000>;
		interrupts = <GIC_SPI 14 IRQ_TYPE_LEVEL_HIGH>,
			     <GIC_SPI 13 IRQ_TYPE_LEVEL_HIGH>;
		arm,pl330-periph-burst;
		clocks = <&cru ACLK_BUS>;
		clock-names = "apb_pclk";
		#dma-cells = <1>;
	};

	dmac1: dmac@fe550000 {
		compatible = "arm,pl330", "arm,primecell";
		reg = <0x0 0xfe550000 0x0 0x4000>;
		interrupts = <GIC_SPI 16 IRQ_TYPE_LEVEL_HIGH>,
			     <GIC_SPI 15 IRQ_TYPE_LEVEL_HIGH>;
		arm,pl330-periph-burst;
		clocks = <&cru ACLK_BUS>;
		clock-names = "apb_pclk";
		#dma-cells = <1>;
	};

	i2c1: i2c@fe5a0000 {
		compatible = "rockchip,rk3568-i2c", "rockchip,rk3399-i2c";
		reg = <0x0 0xfe5a0000 0x0 0x1000>;
		interrupts = <GIC_SPI 47 IRQ_TYPE_LEVEL_HIGH>;
		clocks = <&cru CLK_I2C1>, <&cru PCLK_I2C1>;
		clock-names = "i2c", "pclk";
		pinctrl-0 = <&i2c1_xfer>;
		pinctrl-names = "default";
		#address-cells = <1>;
		#size-cells = <0>;
		status = "disabled";
	};

	i2c2: i2c@fe5b0000 {
		compatible = "rockchip,rk3568-i2c", "rockchip,rk3399-i2c";
		reg = <0x0 0xfe5b0000 0x0 0x1000>;
		interrupts = <GIC_SPI 48 IRQ_TYPE_LEVEL_HIGH>;
		clocks = <&cru CLK_I2C2>, <&cru PCLK_I2C2>;
		clock-names = "i2c", "pclk";
		pinctrl-0 = <&i2c2m0_xfer>;
		pinctrl-names = "default";
		#address-cells = <1>;
		#size-cells = <0>;
		status = "disabled";
	};

	i2c3: i2c@fe5c0000 {
		compatible = "rockchip,rk3568-i2c", "rockchip,rk3399-i2c";
		reg = <0x0 0xfe5c0000 0x0 0x1000>;
		interrupts = <GIC_SPI 49 IRQ_TYPE_LEVEL_HIGH>;
		clocks = <&cru CLK_I2C3>, <&cru PCLK_I2C3>;
		clock-names = "i2c", "pclk";
		pinctrl-0 = <&i2c3m0_xfer>;
		pinctrl-names = "default";
		#address-cells = <1>;
		#size-cells = <0>;
		status = "disabled";
	};

	i2c4: i2c@fe5d0000 {
		compatible = "rockchip,rk3568-i2c", "rockchip,rk3399-i2c";
		reg = <0x0 0xfe5d0000 0x0 0x1000>;
		interrupts = <GIC_SPI 50 IRQ_TYPE_LEVEL_HIGH>;
		clocks = <&cru CLK_I2C4>, <&cru PCLK_I2C4>;
		clock-names = "i2c", "pclk";
		pinctrl-0 = <&i2c4m0_xfer>;
		pinctrl-names = "default";
		#address-cells = <1>;
		#size-cells = <0>;
		status = "disabled";
	};

	i2c5: i2c@fe5e0000 {
		compatible = "rockchip,rk3568-i2c", "rockchip,rk3399-i2c";
		reg = <0x0 0xfe5e0000 0x0 0x1000>;
		interrupts = <GIC_SPI 51 IRQ_TYPE_LEVEL_HIGH>;
		clocks = <&cru CLK_I2C5>, <&cru PCLK_I2C5>;
		clock-names = "i2c", "pclk";
		pinctrl-0 = <&i2c5m0_xfer>;
		pinctrl-names = "default";
		#address-cells = <1>;
		#size-cells = <0>;
		status = "disabled";
	};

	wdt: watchdog@fe600000 {
		compatible = "snps,dw-wdt";
		reg = <0x0 0xfe600000 0x0 0x100>;
		clocks = <&cru TCLK_WDT_NS>, <&cru PCLK_WDT_NS>;
		clock-names = "tclk", "pclk";
		interrupts = <GIC_SPI 149 IRQ_TYPE_LEVEL_HIGH>;
		status = "okay";
	};

	spi0: spi@fe610000 {
		compatible = "rockchip,rk3568-spi", "rockchip,rk3066-spi";
		reg = <0x0 0xfe610000 0x0 0x1000>;
		interrupts = <GIC_SPI 103 IRQ_TYPE_LEVEL_HIGH>;
		#address-cells = <1>;
		#size-cells = <0>;
		clocks = <&cru CLK_SPI0>, <&cru PCLK_SPI0>;
		clock-names = "spiclk", "apb_pclk";
		dmas = <&dmac0 20>, <&dmac0 21>;
		dma-names = "tx", "rx";
		pinctrl-names = "default", "high_speed";
		pinctrl-0 = <&spi0m0_cs0 &spi0m0_cs1 &spi0m0_pins>;
		pinctrl-1 = <&spi0m0_cs0 &spi0m0_cs1 &spi0m0_pins_hs>;
		status = "disabled";
	};

	spi1: spi@fe620000 {
		compatible = "rockchip,rk3568-spi", "rockchip,rk3066-spi";
		reg = <0x0 0xfe620000 0x0 0x1000>;
		interrupts = <GIC_SPI 104 IRQ_TYPE_LEVEL_HIGH>;
		#address-cells = <1>;
		#size-cells = <0>;
		clocks = <&cru CLK_SPI1>, <&cru PCLK_SPI1>;
		clock-names = "spiclk", "apb_pclk";
		dmas = <&dmac0 22>, <&dmac0 23>;
		dma-names = "tx", "rx";
		pinctrl-names = "default", "high_speed";
		pinctrl-0 = <&spi1m0_cs0 &spi1m0_cs1 &spi1m0_pins>;
		pinctrl-1 = <&spi1m0_cs0 &spi1m0_cs1 &spi1m0_pins_hs>;
		status = "disabled";
	};

	spi2: spi@fe630000 {
		compatible = "rockchip,rk3568-spi", "rockchip,rk3066-spi";
		reg = <0x0 0xfe630000 0x0 0x1000>;
		interrupts = <GIC_SPI 105 IRQ_TYPE_LEVEL_HIGH>;
		#address-cells = <1>;
		#size-cells = <0>;
		clocks = <&cru CLK_SPI2>, <&cru PCLK_SPI2>;
		clock-names = "spiclk", "apb_pclk";
		dmas = <&dmac0 24>, <&dmac0 25>;
		dma-names = "tx", "rx";
		pinctrl-names = "default", "high_speed";
		pinctrl-0 = <&spi2m0_cs0 &spi2m0_cs1 &spi2m0_pins>;
		pinctrl-1 = <&spi2m0_cs0 &spi2m0_cs1 &spi2m0_pins_hs>;
		status = "disabled";
	};

	spi3: spi@fe640000 {
		compatible = "rockchip,rk3568-spi", "rockchip,rk3066-spi";
		reg = <0x0 0xfe640000 0x0 0x1000>;
		interrupts = <GIC_SPI 106 IRQ_TYPE_LEVEL_HIGH>;
		#address-cells = <1>;
		#size-cells = <0>;
		clocks = <&cru CLK_SPI3>, <&cru PCLK_SPI3>;
		clock-names = "spiclk", "apb_pclk";
		dmas = <&dmac0 26>, <&dmac0 27>;
		dma-names = "tx", "rx";
		pinctrl-names = "default", "high_speed";
		pinctrl-0 = <&spi3m0_cs0 &spi3m0_cs1 &spi3m0_pins>;
		pinctrl-1 = <&spi3m0_cs0 &spi3m0_cs1 &spi3m0_pins_hs>;
		status = "disabled";
	};

	uart1: serial@fe650000 {
		compatible = "rockchip,rk3568-uart", "snps,dw-apb-uart";
		reg = <0x0 0xfe650000 0x0 0x100>;
		interrupts = <GIC_SPI 117 IRQ_TYPE_LEVEL_HIGH>;
		clocks = <&cru SCLK_UART1>, <&cru PCLK_UART1>;
		clock-names = "baudclk", "apb_pclk";
		dmas = <&dmac0 2>, <&dmac0 3>;
		pinctrl-0 = <&uart1m0_xfer>;
		pinctrl-names = "default";
		reg-io-width = <4>;
		reg-shift = <2>;
		status = "disabled";
	};

	uart2: serial@fe660000 {
		compatible = "rockchip,rk3568-uart", "snps,dw-apb-uart";
		reg = <0x0 0xfe660000 0x0 0x100>;
		interrupts = <GIC_SPI 118 IRQ_TYPE_LEVEL_HIGH>;
		clocks = <&cru SCLK_UART2>, <&cru PCLK_UART2>;
		clock-names = "baudclk", "apb_pclk";
		dmas = <&dmac0 4>, <&dmac0 5>;
		pinctrl-0 = <&uart2m0_xfer>;
		pinctrl-names = "default";
		reg-io-width = <4>;
		reg-shift = <2>;
		status = "disabled";
	};

	uart3: serial@fe670000 {
		compatible = "rockchip,rk3568-uart", "snps,dw-apb-uart";
		reg = <0x0 0xfe670000 0x0 0x100>;
		interrupts = <GIC_SPI 119 IRQ_TYPE_LEVEL_HIGH>;
		clocks = <&cru SCLK_UART3>, <&cru PCLK_UART3>;
		clock-names = "baudclk", "apb_pclk";
		dmas = <&dmac0 6>, <&dmac0 7>;
		pinctrl-0 = <&uart3m0_xfer>;
		pinctrl-names = "default";
		reg-io-width = <4>;
		reg-shift = <2>;
		status = "disabled";
	};

	uart4: serial@fe680000 {
		compatible = "rockchip,rk3568-uart", "snps,dw-apb-uart";
		reg = <0x0 0xfe680000 0x0 0x100>;
		interrupts = <GIC_SPI 120 IRQ_TYPE_LEVEL_HIGH>;
		clocks = <&cru SCLK_UART4>, <&cru PCLK_UART4>;
		clock-names = "baudclk", "apb_pclk";
		dmas = <&dmac0 8>, <&dmac0 9>;
		pinctrl-0 = <&uart4m0_xfer>;
		pinctrl-names = "default";
		reg-io-width = <4>;
		reg-shift = <2>;
		status = "disabled";
	};

	uart5: serial@fe690000 {
		compatible = "rockchip,rk3568-uart", "snps,dw-apb-uart";
		reg = <0x0 0xfe690000 0x0 0x100>;
		interrupts = <GIC_SPI 121 IRQ_TYPE_LEVEL_HIGH>;
		clocks = <&cru SCLK_UART5>, <&cru PCLK_UART5>;
		clock-names = "baudclk", "apb_pclk";
		dmas = <&dmac0 10>, <&dmac0 11>;
		pinctrl-0 = <&uart5m0_xfer>;
		pinctrl-names = "default";
		reg-io-width = <4>;
		reg-shift = <2>;
		status = "disabled";
	};

	uart6: serial@fe6a0000 {
		compatible = "rockchip,rk3568-uart", "snps,dw-apb-uart";
		reg = <0x0 0xfe6a0000 0x0 0x100>;
		interrupts = <GIC_SPI 122 IRQ_TYPE_LEVEL_HIGH>;
		clocks = <&cru SCLK_UART6>, <&cru PCLK_UART6>;
		clock-names = "baudclk", "apb_pclk";
		dmas = <&dmac0 12>, <&dmac0 13>;
		pinctrl-0 = <&uart6m0_xfer>;
		pinctrl-names = "default";
		reg-io-width = <4>;
		reg-shift = <2>;
		status = "disabled";
	};

	uart7: serial@fe6b0000 {
		compatible = "rockchip,rk3568-uart", "snps,dw-apb-uart";
		reg = <0x0 0xfe6b0000 0x0 0x100>;
		interrupts = <GIC_SPI 123 IRQ_TYPE_LEVEL_HIGH>;
		clocks = <&cru SCLK_UART7>, <&cru PCLK_UART7>;
		clock-names = "baudclk", "apb_pclk";
		dmas = <&dmac0 14>, <&dmac0 15>;
		pinctrl-0 = <&uart7m0_xfer>;
		pinctrl-names = "default";
		reg-io-width = <4>;
		reg-shift = <2>;
		status = "disabled";
	};

	uart8: serial@fe6c0000 {
		compatible = "rockchip,rk3568-uart", "snps,dw-apb-uart";
		reg = <0x0 0xfe6c0000 0x0 0x100>;
		interrupts = <GIC_SPI 124 IRQ_TYPE_LEVEL_HIGH>;
		clocks = <&cru SCLK_UART8>, <&cru PCLK_UART8>;
		clock-names = "baudclk", "apb_pclk";
		dmas = <&dmac0 16>, <&dmac0 17>;
		pinctrl-0 = <&uart8m0_xfer>;
		pinctrl-names = "default";
		reg-io-width = <4>;
		reg-shift = <2>;
		status = "disabled";
	};

	uart9: serial@fe6d0000 {
		compatible = "rockchip,rk3568-uart", "snps,dw-apb-uart";
		reg = <0x0 0xfe6d0000 0x0 0x100>;
		interrupts = <GIC_SPI 125 IRQ_TYPE_LEVEL_HIGH>;
		clocks = <&cru SCLK_UART9>, <&cru PCLK_UART9>;
		clock-names = "baudclk", "apb_pclk";
		dmas = <&dmac0 18>, <&dmac0 19>;
		pinctrl-0 = <&uart9m0_xfer>;
		pinctrl-names = "default";
		reg-io-width = <4>;
		reg-shift = <2>;
		status = "disabled";
	};

	pwm4: pwm@fe6e0000 {
		compatible = "rockchip,rk3568-pwm", "rockchip,rk3328-pwm";
		reg = <0x0 0xfe6e0000 0x0 0x10>;
		#pwm-cells = <3>;
		pinctrl-names = "active";
		pinctrl-0 = <&pwm4_pins>;
		clocks = <&cru CLK_PWM1>, <&cru PCLK_PWM1>;
		clock-names = "pwm", "pclk";
		status = "disabled";
	};

	pwm5: pwm@fe6e0010 {
		compatible = "rockchip,rk3568-pwm", "rockchip,rk3328-pwm";
		reg = <0x0 0xfe6e0010 0x0 0x10>;
		#pwm-cells = <3>;
		pinctrl-names = "active";
		pinctrl-0 = <&pwm5_pins>;
		clocks = <&cru CLK_PWM1>, <&cru PCLK_PWM1>;
		clock-names = "pwm", "pclk";
		status = "disabled";
	};

	pwm6: pwm@fe6e0020 {
		compatible = "rockchip,rk3568-pwm", "rockchip,rk3328-pwm";
		reg = <0x0 0xfe6e0020 0x0 0x10>;
		#pwm-cells = <3>;
		pinctrl-names = "active";
		pinctrl-0 = <&pwm6_pins>;
		clocks = <&cru CLK_PWM1>, <&cru PCLK_PWM1>;
		clock-names = "pwm", "pclk";
		status = "disabled";
	};

	pwm7: pwm@fe6e0030 {
		compatible = "rockchip,rk3568-pwm", "rockchip,rk3328-pwm";
		reg = <0x0 0xfe6e0030 0x0 0x10>;
		#pwm-cells = <3>;
		pinctrl-names = "active";
		pinctrl-0 = <&pwm7_pins>;
		clocks = <&cru CLK_PWM1>, <&cru PCLK_PWM1>;
		clock-names = "pwm", "pclk";
		status = "disabled";
	};

	pwm8: pwm@fe6f0000 {
		compatible = "rockchip,rk3568-pwm", "rockchip,rk3328-pwm";
		reg = <0x0 0xfe6f0000 0x0 0x10>;
		#pwm-cells = <3>;
		pinctrl-names = "active";
		pinctrl-0 = <&pwm8m0_pins>;
		clocks = <&cru CLK_PWM2>, <&cru PCLK_PWM2>;
		clock-names = "pwm", "pclk";
		status = "disabled";
	};

	pwm9: pwm@fe6f0010 {
		compatible = "rockchip,rk3568-pwm", "rockchip,rk3328-pwm";
		reg = <0x0 0xfe6f0010 0x0 0x10>;
		#pwm-cells = <3>;
		pinctrl-names = "active";
		pinctrl-0 = <&pwm9m0_pins>;
		clocks = <&cru CLK_PWM2>, <&cru PCLK_PWM2>;
		clock-names = "pwm", "pclk";
		status = "disabled";
	};

	pwm10: pwm@fe6f0020 {
		compatible = "rockchip,rk3568-pwm", "rockchip,rk3328-pwm";
		reg = <0x0 0xfe6f0020 0x0 0x10>;
		#pwm-cells = <3>;
		pinctrl-names = "active";
		pinctrl-0 = <&pwm10m0_pins>;
		clocks = <&cru CLK_PWM2>, <&cru PCLK_PWM2>;
		clock-names = "pwm", "pclk";
		status = "disabled";
	};

	pwm11: pwm@fe6f0030 {
		compatible = "rockchip,rk3568-pwm", "rockchip,rk3328-pwm";
		reg = <0x0 0xfe6f0030 0x0 0x10>;
		#pwm-cells = <3>;
		pinctrl-names = "active";
		pinctrl-0 = <&pwm11m0_pins>;
		clocks = <&cru CLK_PWM2>, <&cru PCLK_PWM2>;
		clock-names = "pwm", "pclk";
		status = "disabled";
	};

	pwm12: pwm@fe700000 {
		compatible = "rockchip,rk3568-pwm", "rockchip,rk3328-pwm";
		reg = <0x0 0xfe700000 0x0 0x10>;
		#pwm-cells = <3>;
		pinctrl-names = "active";
		pinctrl-0 = <&pwm12m0_pins>;
		clocks = <&cru CLK_PWM3>, <&cru PCLK_PWM3>;
		clock-names = "pwm", "pclk";
		status = "disabled";
	};

	pwm13: pwm@fe700010 {
		compatible = "rockchip,rk3568-pwm", "rockchip,rk3328-pwm";
		reg = <0x0 0xfe700010 0x0 0x10>;
		#pwm-cells = <3>;
		pinctrl-names = "active";
		pinctrl-0 = <&pwm13m0_pins>;
		clocks = <&cru CLK_PWM3>, <&cru PCLK_PWM3>;
		clock-names = "pwm", "pclk";
		status = "disabled";
	};

	pwm14: pwm@fe700020 {
		compatible = "rockchip,rk3568-pwm", "rockchip,rk3328-pwm";
		reg = <0x0 0xfe700020 0x0 0x10>;
		#pwm-cells = <3>;
		pinctrl-names = "active";
		pinctrl-0 = <&pwm14m0_pins>;
		clocks = <&cru CLK_PWM3>, <&cru PCLK_PWM3>;
		clock-names = "pwm", "pclk";
		status = "disabled";
	};

	pwm15: pwm@fe700030 {
		compatible = "rockchip,rk3568-pwm", "rockchip,rk3328-pwm";
		reg = <0x0 0xfe700030 0x0 0x10>;
		#pwm-cells = <3>;
		pinctrl-names = "active";
		pinctrl-0 = <&pwm15m0_pins>;
		clocks = <&cru CLK_PWM3>, <&cru PCLK_PWM3>;
		clock-names = "pwm", "pclk";
		status = "disabled";
	};

	tsadc: tsadc@fe710000 {
		compatible = "rockchip,rk3568-tsadc";
		reg = <0x0 0xfe710000 0x0 0x100>;
		interrupts = <GIC_SPI 115 IRQ_TYPE_LEVEL_HIGH>;
		rockchip,grf = <&grf>;
		clocks = <&cru CLK_TSADC>, <&cru PCLK_TSADC>;
		clock-names = "tsadc", "apb_pclk";
		assigned-clocks = <&cru CLK_TSADC_TSEN>, <&cru CLK_TSADC>;
		assigned-clock-rates = <17000000>, <700000>;
		resets = <&cru SRST_TSADC>, <&cru SRST_P_TSADC>,
			 <&cru SRST_TSADCPHY>;
		reset-names = "tsadc", "tsadc-apb", "tsadc-phy";
		#thermal-sensor-cells = <1>;
		rockchip,hw-tshut-temp = <120000>;
		rockchip,hw-tshut-mode = <1>; /* tshut mode 0:CRU 1:GPIO */
		rockchip,hw-tshut-polarity = <0>; /* tshut polarity 0:LOW 1:HIGH */
		pinctrl-names = "gpio", "otpout";
		pinctrl-0 = <&tsadc_gpio>;
		pinctrl-1 = <&tsadc_shutorg>;
		status = "disabled";
	};

	saradc: saradc@fe720000 {
		compatible = "rockchip,rk3568-saradc", "rockchip,rk3399-saradc";
		reg = <0x0 0xfe720000 0x0 0x100>;
		interrupts = <GIC_SPI 93 IRQ_TYPE_LEVEL_HIGH>;
		#io-channel-cells = <1>;
		clocks = <&cru CLK_SARADC>, <&cru PCLK_SARADC>;
		clock-names = "saradc", "apb_pclk";
		resets = <&cru SRST_P_SARADC>;
		reset-names = "saradc-apb";
		status = "disabled";
	};

	mailbox: mailbox@fe780000 {
		compatible = "rockchip,rk3568-mailbox", "rockchip,rk3368-mailbox";
		reg = <0x0 0xfe780000 0x0 0x1000>;
		interrupts = <GIC_SPI 183 IRQ_TYPE_LEVEL_HIGH>,
			     <GIC_SPI 184 IRQ_TYPE_LEVEL_HIGH>,
			     <GIC_SPI 185 IRQ_TYPE_LEVEL_HIGH>,
			     <GIC_SPI 186 IRQ_TYPE_LEVEL_HIGH>;
		clocks = <&cru PCLK_MAILBOX>;
		clock-names = "pclk_mailbox";
		#mbox-cells = <1>;
		status = "disabled";
	};

	combphy0_us: phy@fe820000 {
		compatible = "rockchip,rk3568-naneng-combphy";
		reg = <0x0 0xfe820000 0x0 0x100>;
		#phy-cells = <1>;
		clocks = <&pmucru CLK_PCIEPHY0_REF>, <&cru PCLK_PIPEPHY0>,
			 <&cru PCLK_PIPE>;
		clock-names = "refclk", "apbclk", "pipe_clk";
		assigned-clocks = <&pmucru CLK_PCIEPHY0_REF>;
		assigned-clock-rates = <24000000>;
		resets = <&cru SRST_P_PIPEPHY0>, <&cru SRST_PIPEPHY0>;
		reset-names = "combphy-apb", "combphy";
		rockchip,pipe-grf = <&pipegrf>;
		rockchip,pipe-phy-grf = <&pipe_phy_grf0>;
		status = "disabled";
	};

	combphy1_usq: phy@fe830000 {
		compatible = "rockchip,rk3568-naneng-combphy";
		reg = <0x0 0xfe830000 0x0 0x100>;
		#phy-cells = <1>;
		clocks = <&pmucru CLK_PCIEPHY1_REF>, <&cru PCLK_PIPEPHY1>,
			 <&cru PCLK_PIPE>;
		clock-names = "refclk", "apbclk", "pipe_clk";
		assigned-clocks = <&pmucru CLK_PCIEPHY1_REF>;
		assigned-clock-rates = <24000000>;
		resets = <&cru SRST_P_PIPEPHY1>, <&cru SRST_PIPEPHY1>;
		reset-names = "combphy-apb", "combphy";
		rockchip,pipe-grf = <&pipegrf>;
		rockchip,pipe-phy-grf = <&pipe_phy_grf1>;
		status = "disabled";
	};

	combphy2_psq: phy@fe840000 {
		compatible = "rockchip,rk3568-naneng-combphy";
		reg = <0x0 0xfe840000 0x0 0x100>;
		#phy-cells = <1>;
		clocks = <&pmucru CLK_PCIEPHY2_REF>, <&cru PCLK_PIPEPHY2>,
			 <&cru PCLK_PIPE>;
		clock-names = "refclk", "apbclk", "pipe_clk";
		assigned-clocks = <&pmucru CLK_PCIEPHY2_REF>;
		assigned-clock-rates = <24000000>;
		resets = <&cru SRST_P_PIPEPHY2>, <&cru SRST_PIPEPHY2>;
		reset-names = "combphy-apb", "combphy";
		rockchip,pipe-grf = <&pipegrf>;
		rockchip,pipe-phy-grf = <&pipe_phy_grf2>;
		status = "disabled";
	};

	usb2phy0: usb2-phy@fe8a0000 {
		compatible = "rockchip,rk3568-usb2phy";
		reg = <0x0 0xfe8a0000 0x0 0x10000>;
		interrupts = <GIC_SPI 135 IRQ_TYPE_LEVEL_HIGH>;
		clocks = <&pmucru CLK_USBPHY0_REF>;
		clock-names = "phyclk";
		#clock-cells = <0>;
		assigned-clocks = <&cru USB480M>;
		assigned-clock-parents = <&usb2phy0>;
		clock-output-names = "usb480m_phy";
		rockchip,usbgrf = <&usb2phy0_grf>;
		status = "disabled";

		u2phy0_host: host-port {
			#phy-cells = <0>;
			status = "disabled";
		};

		u2phy0_otg: otg-port {
			#phy-cells = <0>;
			status = "disabled";
		};
	};

	usb2phy1: usb2-phy@fe8b0000 {
		compatible = "rockchip,rk3568-usb2phy";
		reg = <0x0 0xfe8b0000 0x0 0x10000>;
		interrupts = <GIC_SPI 136 IRQ_TYPE_LEVEL_HIGH>;
		clocks = <&pmucru CLK_USBPHY1_REF>;
		clock-names = "phyclk";
		#clock-cells = <0>;
		rockchip,usbgrf = <&usb2phy1_grf>;
		status = "disabled";

		u2phy1_host: host-port {
			#phy-cells = <0>;
			status = "disabled";
		};

		u2phy1_otg: otg-port {
			#phy-cells = <0>;
			status = "disabled";
		};
	};

	pcie30phy: phy@fe8c0000 {
		compatible = "rockchip,rk3568-pcie3-phy";
		reg = <0x0 0xfe8c0000 0x0 0x20000>;
		#phy-cells = <0>;
		clocks = <&pmucru CLK_PCIE30PHY_REF_M>, <&pmucru CLK_PCIE30PHY_REF_N>,
			 <&cru PCLK_PCIE30PHY>;
		clock-names = "refclk_m", "refclk_n", "pclk";
		resets = <&cru SRST_PCIE30PHY>;
		reset-names = "phy";
		rockchip,phy-grf = <&pcie30_phy_grf>;
		status = "disabled";
	};

	pinctrl: pinctrl {
		compatible = "rockchip,rk3568-pinctrl";
		rockchip,grf = <&grf>;
		rockchip,pmu = <&pmugrf>;
		#address-cells = <2>;
		#size-cells = <2>;
		ranges;

		gpio0: gpio@fdd60000 {
			compatible = "rockchip,gpio-bank";
			reg = <0x0 0xfdd60000 0x0 0x100>;
			interrupts = <GIC_SPI 33 IRQ_TYPE_LEVEL_HIGH>;
			clocks = <&pmucru PCLK_GPIO0>, <&pmucru DBCLK_GPIO0>;

			gpio-controller;
			#gpio-cells = <2>;
			interrupt-controller;
			#interrupt-cells = <2>;
		};

		gpio1: gpio@fe740000 {
			compatible = "rockchip,gpio-bank";
			reg = <0x0 0xfe740000 0x0 0x100>;
			interrupts = <GIC_SPI 34 IRQ_TYPE_LEVEL_HIGH>;
			clocks = <&cru PCLK_GPIO1>, <&cru DBCLK_GPIO1>;

			gpio-controller;
			#gpio-cells = <2>;
			interrupt-controller;
			#interrupt-cells = <2>;
		};

		gpio2: gpio@fe750000 {
			compatible = "rockchip,gpio-bank";
			reg = <0x0 0xfe750000 0x0 0x100>;
			interrupts = <GIC_SPI 35 IRQ_TYPE_LEVEL_HIGH>;
			clocks = <&cru PCLK_GPIO2>, <&cru DBCLK_GPIO2>;

			gpio-controller;
			#gpio-cells = <2>;
			interrupt-controller;
			#interrupt-cells = <2>;
		};

		gpio3: gpio@fe760000 {
			compatible = "rockchip,gpio-bank";
			reg = <0x0 0xfe760000 0x0 0x100>;
			interrupts = <GIC_SPI 36 IRQ_TYPE_LEVEL_HIGH>;
			clocks = <&cru PCLK_GPIO3>, <&cru DBCLK_GPIO3>;

			gpio-controller;
			#gpio-cells = <2>;
			interrupt-controller;
			#interrupt-cells = <2>;
		};

		gpio4: gpio@fe770000 {
			compatible = "rockchip,gpio-bank";
			reg = <0x0 0xfe770000 0x0 0x100>;
			interrupts = <GIC_SPI 37 IRQ_TYPE_LEVEL_HIGH>;
			clocks = <&cru PCLK_GPIO4>, <&cru DBCLK_GPIO4>;

			gpio-controller;
			#gpio-cells = <2>;
			interrupt-controller;
			#interrupt-cells = <2>;
		};
	};
};

#include "rk3568-pinctrl.dtsi"
